AUTOSAR XML (schema 00051)
package /ComponentTypes
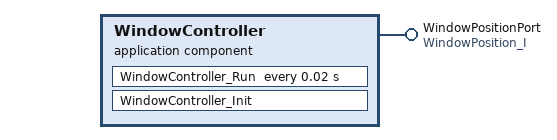
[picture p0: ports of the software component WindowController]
  application sw component type WindowController
    provide port WindowPositionPort: nonqueued-sender-com-spec{data-element=WindowPosition, init-value=constant-reference=WindowPosition_IV}, provided-interface=WindowPosition_I
    behavior WindowController_InternalBehavior
      init event IT_WindowController_Init: start-on-event=WindowController_Init
      timing event TMT_WindowController_Run: start-on-event=WindowController_Run, period=0.02
      runnable WindowController_Init
      runnable WindowController_Run
        data-send-points:
          access SEND_WindowPositionPort_WindowPosition: accessed-variable=WindowPositionPort.WindowPosition
  swc implementation WindowController_Implementation: behavior=WindowController_InternalBehavior
